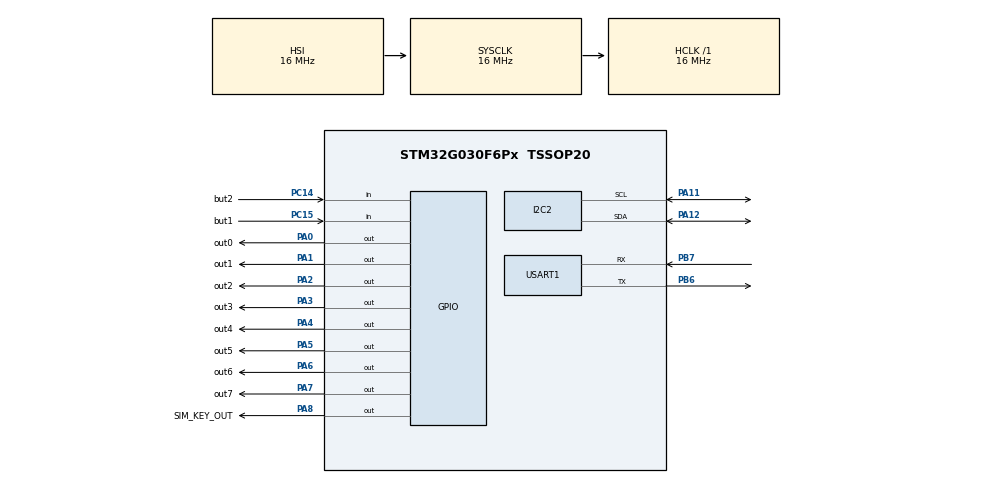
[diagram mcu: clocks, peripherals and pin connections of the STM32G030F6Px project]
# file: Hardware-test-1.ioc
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Mcu.Family=STM32G0
Mcu.Name=STM32G030F6Px
Mcu.Package=TSSOP20
NVIC.TIM14_IRQn=true\:0\:0\:false\:false\:true\:true\:true
PA0.GPIO_Label=out0
PA0.PinState=GPIO_PIN_SET
PA0.Signal=GPIO_Output
PA1.GPIO_Label=out1
PA1.PinState=GPIO_PIN_SET
PA1.Signal=GPIO_Output
PA11\ [PA9].Mode=I2C
PA11\ [PA9].Signal=I2C2_SCL
PA12\ [PA10].Mode=I2C
PA12\ [PA10].Signal=I2C2_SDA
PA13.Mode=Serial_Wire
PA13.Signal=SYS_SWDIO
PA14-BOOT0.Mode=Serial_Wire
PA14-BOOT0.Signal=SYS_SWCLK
PA2.GPIO_Label=out2
PA2.PinState=GPIO_PIN_SET
PA2.Signal=GPIO_Output
PA3.GPIO_Label=out3
PA3.PinState=GPIO_PIN_SET
PA3.Signal=GPIO_Output
PA4.GPIO_Label=out4
PA4.PinState=GPIO_PIN_SET
PA4.Signal=GPIO_Output
PA5.GPIO_Label=out5
PA5.PinState=GPIO_PIN_SET
PA5.Signal=GPIO_Output
PA6.GPIO_Label=out6
PA6.PinState=GPIO_PIN_SET
PA6.Signal=GPIO_Output
PA7.GPIO_Label=out7
PA7.PinState=GPIO_PIN_SET
PA7.Signal=GPIO_Output
PA8.GPIO_Label=SIM_KEY_OUT
PA8.PinState=GPIO_PIN_SET
PA8.Signal=GPIO_Output
PB6.Mode=Asynchronous
PB6.Signal=USART1_TX
PB7.Mode=Asynchronous
PB7.Signal=USART1_RX
PC14-OSC32_IN\ (PC14).GPIO_Label=but2
PC14-OSC32_IN\ (PC14).GPIO_PuPd=GPIO_PULLUP
PC14-OSC32_IN\ (PC14).Signal=GPIO_Input
PC15-OSC32_OUT\ (PC15).GPIO_Label=but1
PC15-OSC32_OUT\ (PC15).GPIO_PuPd=GPIO_PULLUP
PC15-OSC32_OUT\ (PC15).Signal=GPIO_Input
ProjectManager.HeapSize=0x200
ProjectManager.StackSize=0x400
ProjectManager.TargetToolchain=STM32CubeIDE
RCC.AHBFreq_Value=16000000
RCC.CortexFreq_Value=16000000
RCC.EXTERNAL_CLOCK_VALUE=12288000
RCC.HCLKFreq_Value=16000000
RCC.HSE_VALUE=8000000
RCC.HSI_VALUE=16000000
RCC.LSE_VALUE=32768
RCC.SYSCLKFreq_VALUE=16000000
RCC.VCOOutputFreq_Value=128000000
RTC.Date=3
RTC.Hours=15
RTC.Minutes=30
RTC.Month=RTC_MONTH_JUNE
RTC.WeekDay=RTC_WEEKDAY_FRIDAY
RTC.Year=20
TIM14.AutoReloadPreload=TIM_AUTORELOAD_PRELOAD_DISABLE
TIM14.ClockDivision=TIM_CLOCKDIVISION_DIV1
TIM14.Period=100-1
TIM14.Prescaler=16-1
USART1.VirtualMode-Asynchronous=VM_ASYNC
VP_RTC_VS_RTC_Activate.Mode=RTC_Enabled
VP_RTC_VS_RTC_Calendar.Mode=RTC_Calendar
VP_TIM14_VS_ClockSourceINT.Mode=Enable_Timer
board=custom

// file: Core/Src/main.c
/* USER CODE BEGIN Header */
/**
  ******************************************************************************
  * @file           : main.c
  * @brief          : Main program body
  ******************************************************************************
  * @attention
  *
  * Copyright (c) 2022 STMicroelectronics.
  * All rights reserved.
  *
  * This software is licensed under terms that can be found in the LICENSE file
  * in the root directory of this software component.
  * If no LICENSE file comes with this software, it is provided AS-IS.
  *
  ******************************************************************************
  */
/* USER CODE END Header */

/* USER CODE BEGIN Includes */
#include "string.h"
#include "stdint.h"
#include "stdio.h"
#include "defs.h"
#include "funcs.h"
#include "main.h"

/* USER CODE END Includes */

void SystemClock_Config(void);
static void MX_GPIO_Init(void);
static void MX_I2C2_Init(void);
static void MX_RTC_Init(void);
static void MX_USART1_UART_Init(void);
static void MX_TIM14_Init(void);

int main(void)
{

  /* MCU Configuration--------------------------------------------------------*/

  /* Reset of all peripherals, Initializes the Flash interface and the Systick. */
  HAL_Init();

  /* Configure the system clock */
  SystemClock_Config();

  /* Initialize all configured peripherals */
  MX_GPIO_Init();
  MX_I2C2_Init();
  MX_RTC_Init();
  MX_USART1_UART_Init();
  MX_TIM14_Init();
  /* USER CODE BEGIN 2 */
  HAL_TIM_Base_Start_IT(&htim14);
  /* USER CODE END 2 */

  /* Infinite loop */
  while (1)
  {

    /* USER CODE BEGIN 3 */

	scanBus();

	while(1){
		doLoop();
		//HAL_Delay(50);
	}
  }
  /* USER CODE END 3 */
}

void SystemClock_Config(void)
{
  RCC_OscInitTypeDef RCC_OscInitStruct = {0};
  RCC_ClkInitTypeDef RCC_ClkInitStruct = {0};

  /** Configure the main internal regulator output voltage
  */
  HAL_PWREx_ControlVoltageScaling(PWR_REGULATOR_VOLTAGE_SCALE1);
  /** Initializes the RCC Oscillators according to the specified parameters
  * in the RCC_OscInitTypeDef structure.
  */
  RCC_OscInitStruct.OscillatorType = RCC_OSCILLATORTYPE_HSI|RCC_OSCILLATORTYPE_LSI;
  RCC_OscInitStruct.HSIState = RCC_HSI_ON;
  RCC_OscInitStruct.HSIDiv = RCC_HSI_DIV1;
  RCC_OscInitStruct.HSICalibrationValue = RCC_HSICALIBRATION_DEFAULT;
  RCC_OscInitStruct.LSIState = RCC_LSI_ON;
  RCC_OscInitStruct.PLL.PLLState = RCC_PLL_NONE;
  if (HAL_RCC_OscConfig(&RCC_OscInitStruct) != HAL_OK)
  {
    Error_Handler();
  }
  /** Initializes the CPU, AHB and APB buses clocks
  */
  RCC_ClkInitStruct.ClockType = RCC_CLOCKTYPE_HCLK|RCC_CLOCKTYPE_SYSCLK
                              |RCC_CLOCKTYPE_PCLK1;
  RCC_ClkInitStruct.SYSCLKSource = RCC_SYSCLKSOURCE_HSI;
  RCC_ClkInitStruct.AHBCLKDivider = RCC_SYSCLK_DIV1;
  RCC_ClkInitStruct.APB1CLKDivider = RCC_HCLK_DIV1;

  if (HAL_RCC_ClockConfig(&RCC_ClkInitStruct, FLASH_LATENCY_0) != HAL_OK)
  {
    Error_Handler();
  }
}

static void MX_I2C2_Init(void)
{

  hi2c2.Instance = I2C2;
  hi2c2.Init.Timing = 0x00303D5B;
  hi2c2.Init.OwnAddress1 = 0;
  hi2c2.Init.AddressingMode = I2C_ADDRESSINGMODE_7BIT;
  hi2c2.Init.DualAddressMode = I2C_DUALADDRESS_DISABLE;
  hi2c2.Init.OwnAddress2 = 0;
  hi2c2.Init.OwnAddress2Masks = I2C_OA2_NOMASK;
  hi2c2.Init.GeneralCallMode = I2C_GENERALCALL_DISABLE;
  hi2c2.Init.NoStretchMode = I2C_NOSTRETCH_DISABLE;
  if (HAL_I2C_Init(&hi2c2) != HAL_OK)
  {
    Error_Handler();
  }
  /** Configure Analogue filter
  */
  if (HAL_I2CEx_ConfigAnalogFilter(&hi2c2, I2C_ANALOGFILTER_ENABLE) != HAL_OK)
  {
    Error_Handler();
  }
  /** Configure Digital filter
  */
  if (HAL_I2CEx_ConfigDigitalFilter(&hi2c2, 0) != HAL_OK)
  {
    Error_Handler();
  }

}

static void MX_RTC_Init(void)
{

  RTC_TimeTypeDef sTime = {0};
  RTC_DateTypeDef sDate = {0};

  /** Initialize RTC Only
  */
  hrtc.Instance = RTC;
  hrtc.Init.HourFormat = RTC_HOURFORMAT_24;
  hrtc.Init.AsynchPrediv = 127;
  hrtc.Init.SynchPrediv = 255;
  hrtc.Init.OutPut = RTC_OUTPUT_DISABLE;
  hrtc.Init.OutPutRemap = RTC_OUTPUT_REMAP_NONE;
  hrtc.Init.OutPutPolarity = RTC_OUTPUT_POLARITY_HIGH;
  hrtc.Init.OutPutType = RTC_OUTPUT_TYPE_OPENDRAIN;
  hrtc.Init.OutPutPullUp = RTC_OUTPUT_PULLUP_NONE;
  if (HAL_RTC_Init(&hrtc) != HAL_OK)
  {
    Error_Handler();
  }

  /** Initialize RTC and set the Time and Date
  */
  sTime.Hours = 0x15;
  sTime.Minutes = 0x30;
  sTime.Seconds = 0x0;
  sTime.SubSeconds = 0x0;
  sTime.DayLightSaving = RTC_DAYLIGHTSAVING_NONE;
  sTime.StoreOperation = RTC_STOREOPERATION_RESET;
  if (HAL_RTC_SetTime(&hrtc, &sTime, RTC_FORMAT_BCD) != HAL_OK)
  {
    Error_Handler();
  }
  sDate.WeekDay = RTC_WEEKDAY_FRIDAY;
  sDate.Month = RTC_MONTH_JUNE;
  sDate.Date = 0x3;
  sDate.Year = 0x20;

  if (HAL_RTC_SetDate(&hrtc, &sDate, RTC_FORMAT_BCD) != HAL_OK)
  {
    Error_Handler();
  }

}

static void MX_TIM14_Init(void)
{

  htim14.Instance = TIM14;
  htim14.Init.Prescaler = 16-1;
  htim14.Init.CounterMode = TIM_COUNTERMODE_UP;
  htim14.Init.Period = 100-1;
  htim14.Init.ClockDivision = TIM_CLOCKDIVISION_DIV1;
  htim14.Init.AutoReloadPreload = TIM_AUTORELOAD_PRELOAD_DISABLE;
  if (HAL_TIM_Base_Init(&htim14) != HAL_OK)
  {
    Error_Handler();
  }

}

static void MX_USART1_UART_Init(void)
{

  huart1.Instance = USART1;
  huart1.Init.BaudRate = 115200;
  huart1.Init.WordLength = UART_WORDLENGTH_8B;
  huart1.Init.StopBits = UART_STOPBITS_1;
  huart1.Init.Parity = UART_PARITY_NONE;
  huart1.Init.Mode = UART_MODE_TX_RX;
  huart1.Init.HwFlowCtl = UART_HWCONTROL_NONE;
  huart1.Init.OverSampling = UART_OVERSAMPLING_16;
  huart1.Init.OneBitSampling = UART_ONE_BIT_SAMPLE_DISABLE;
  huart1.Init.ClockPrescaler = UART_PRESCALER_DIV1;
  huart1.AdvancedInit.AdvFeatureInit = UART_ADVFEATURE_NO_INIT;
  if (HAL_UART_Init(&huart1) != HAL_OK)
  {
    Error_Handler();
  }
  if (HAL_UARTEx_SetTxFifoThreshold(&huart1, UART_TXFIFO_THRESHOLD_1_8) != HAL_OK)
  {
    Error_Handler();
  }
  if (HAL_UARTEx_SetRxFifoThreshold(&huart1, UART_RXFIFO_THRESHOLD_1_8) != HAL_OK)
  {
    Error_Handler();
  }
  if (HAL_UARTEx_DisableFifoMode(&huart1) != HAL_OK)
  {
    Error_Handler();
  }

}

static void MX_GPIO_Init(void)
{
  GPIO_InitTypeDef GPIO_InitStruct = {0};

  /* GPIO Ports Clock Enable */
  __HAL_RCC_GPIOB_CLK_ENABLE();
  __HAL_RCC_GPIOC_CLK_ENABLE();
  __HAL_RCC_GPIOA_CLK_ENABLE();

  /*Configure GPIO pin Output Level */
  HAL_GPIO_WritePin(GPIOA, out0_Pin|out1_Pin|out2_Pin|out3_Pin
                          |out4_Pin|out5_Pin|out6_Pin|out7_Pin
                          |SIM_KEY_OUT_Pin, GPIO_PIN_SET);

  /*Configure GPIO pins : but2_Pin but1_Pin */
  GPIO_InitStruct.Pin = but2_Pin|but1_Pin;
  GPIO_InitStruct.Mode = GPIO_MODE_INPUT;
  GPIO_InitStruct.Pull = GPIO_PULLUP;
  HAL_GPIO_Init(GPIOC, &GPIO_InitStruct);

  /*Configure GPIO pins : out0_Pin out1_Pin out2_Pin out3_Pin
                           out4_Pin out5_Pin out6_Pin out7_Pin
                           SIM_KEY_OUT_Pin */
  GPIO_InitStruct.Pin = out0_Pin|out1_Pin|out2_Pin|out3_Pin
                          |out4_Pin|out5_Pin|out6_Pin|out7_Pin
                          |SIM_KEY_OUT_Pin;
  GPIO_InitStruct.Mode = GPIO_MODE_OUTPUT_PP;
  GPIO_InitStruct.Pull = GPIO_NOPULL;
  GPIO_InitStruct.Speed = GPIO_SPEED_FREQ_LOW;
  HAL_GPIO_Init(GPIOA, &GPIO_InitStruct);

}

void Error_Handler(void)
{
  __disable_irq();
  while (1)
  {
  }
}
